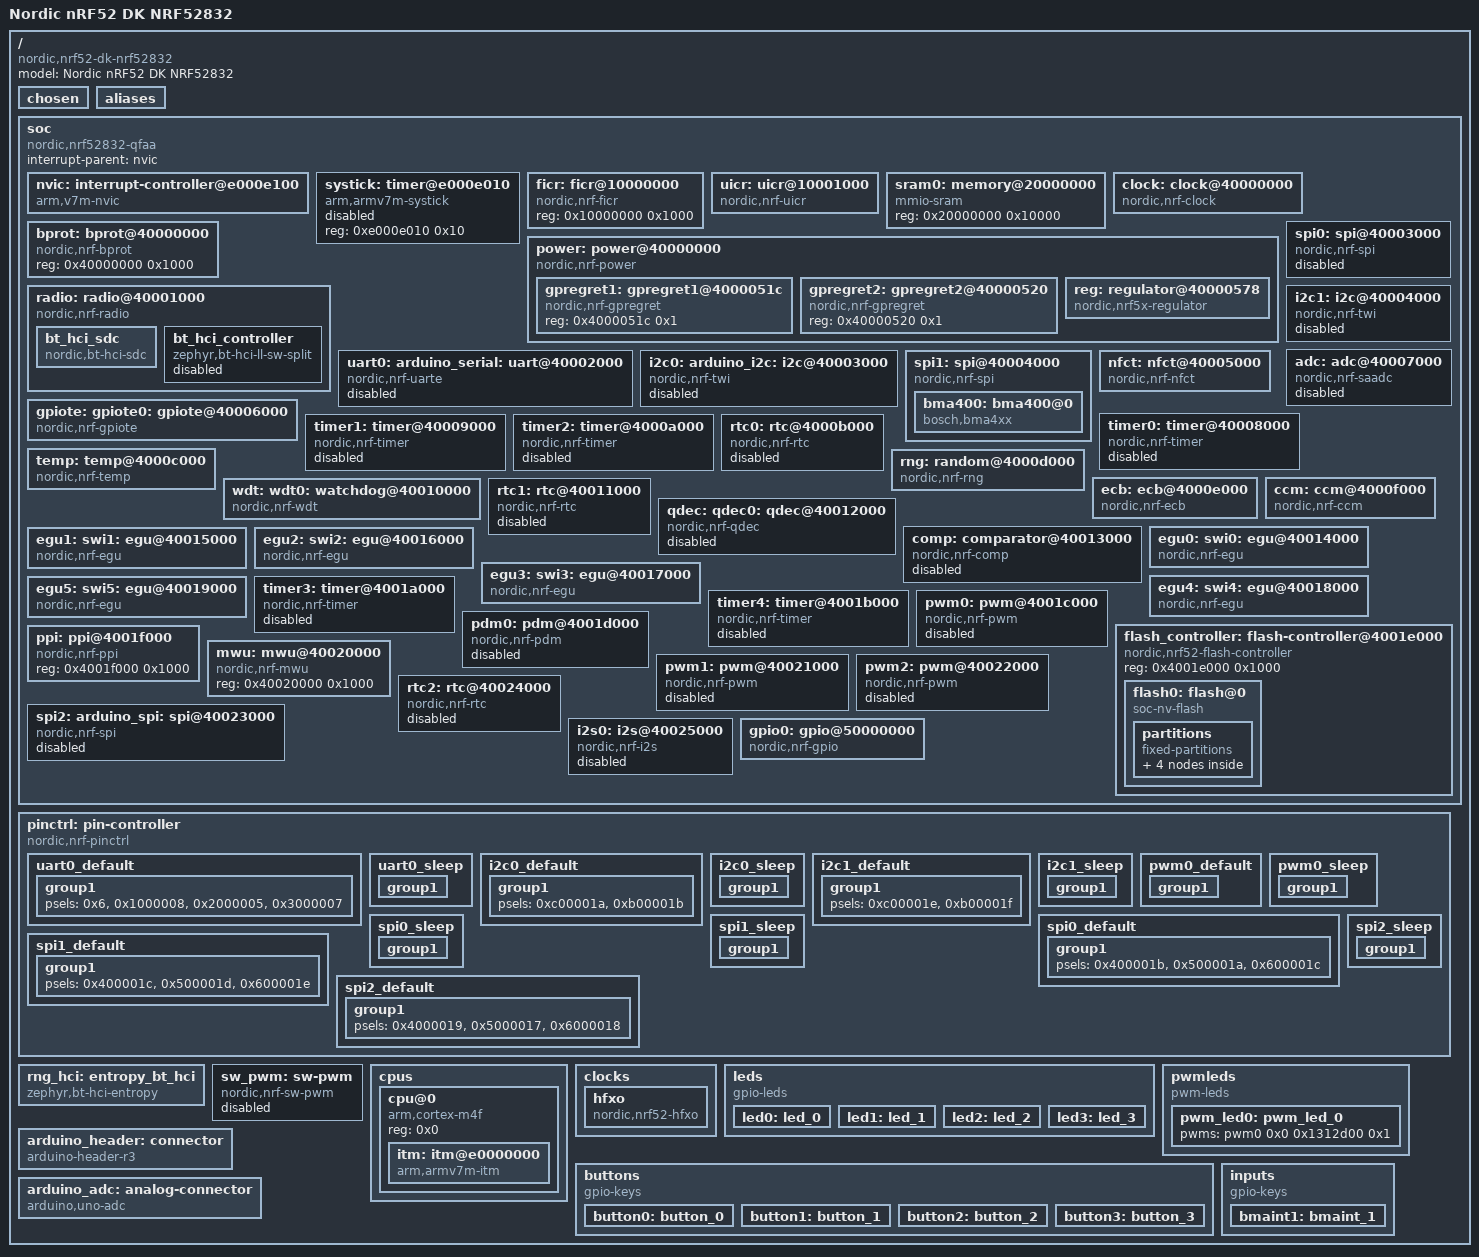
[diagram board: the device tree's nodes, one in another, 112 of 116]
/dts-v1/;

/* node '/' defined in zephyr/dts/common/skeleton.dtsi:9 */
/ {
	#address-cells = < 0x1 >;                /* in zephyr/dts/common/skeleton.dtsi:10 */
	#size-cells = < 0x1 >;                   /* in zephyr/dts/common/skeleton.dtsi:11 */
	model = "Nordic nRF52 DK NRF52832";      /* in zephyr/boards/nordic/nrf52dk/nrf52dk_nrf52832.dts:14 */
	compatible = "nordic,nrf52-dk-nrf52832"; /* in zephyr/boards/nordic/nrf52dk/nrf52dk_nrf52832.dts:15 */

	/* node '/chosen' defined in zephyr/dts/common/skeleton.dtsi:12 */
	chosen {
		zephyr,bt-hci = &bt_hci_sdc;                 /* in zephyr/dts/arm/nordic/nrf52832.dtsi:10 */
		zephyr,entropy = &rng;                       /* in zephyr/dts/arm/nordic/nrf52832.dtsi:11 */
		zephyr,flash-controller = &flash_controller; /* in zephyr/dts/arm/nordic/nrf52832.dtsi:12 */
		zephyr,console = &uart0;                     /* in zephyr/boards/nordic/nrf52dk/nrf52dk_nrf52832.dts:18 */
		zephyr,shell-uart = &uart0;                  /* in zephyr/boards/nordic/nrf52dk/nrf52dk_nrf52832.dts:19 */
		zephyr,uart-mcumgr = &uart0;                 /* in zephyr/boards/nordic/nrf52dk/nrf52dk_nrf52832.dts:20 */
		zephyr,bt-mon-uart = &uart0;                 /* in zephyr/boards/nordic/nrf52dk/nrf52dk_nrf52832.dts:21 */
		zephyr,bt-c2h-uart = &uart0;                 /* in zephyr/boards/nordic/nrf52dk/nrf52dk_nrf52832.dts:22 */
		zephyr,sram = &sram0;                        /* in zephyr/boards/nordic/nrf52dk/nrf52dk_nrf52832.dts:23 */
		zephyr,flash = &flash0;                      /* in zephyr/boards/nordic/nrf52dk/nrf52dk_nrf52832.dts:24 */
		zephyr,code-partition = &slot0_partition;    /* in zephyr/boards/nordic/nrf52dk/nrf52dk_nrf52832.dts:25 */
	};

	/* node '/aliases' defined in zephyr/dts/common/skeleton.dtsi:13 */
	aliases {
		led0 = &led0;               /* in zephyr/boards/nordic/nrf52dk/nrf52dk_nrf52832.dts:130 */
		led1 = &led1;               /* in zephyr/boards/nordic/nrf52dk/nrf52dk_nrf52832.dts:131 */
		led2 = &led2;               /* in zephyr/boards/nordic/nrf52dk/nrf52dk_nrf52832.dts:132 */
		led3 = &led3;               /* in zephyr/boards/nordic/nrf52dk/nrf52dk_nrf52832.dts:133 */
		pwm-led0 = &pwm_led0;       /* in zephyr/boards/nordic/nrf52dk/nrf52dk_nrf52832.dts:134 */
		sw0 = &button0;             /* in zephyr/boards/nordic/nrf52dk/nrf52dk_nrf52832.dts:135 */
		sw1 = &button1;             /* in zephyr/boards/nordic/nrf52dk/nrf52dk_nrf52832.dts:136 */
		sw2 = &button2;             /* in zephyr/boards/nordic/nrf52dk/nrf52dk_nrf52832.dts:137 */
		sw3 = &button3;             /* in zephyr/boards/nordic/nrf52dk/nrf52dk_nrf52832.dts:138 */
		bootloader-led0 = &led0;    /* in zephyr/boards/nordic/nrf52dk/nrf52dk_nrf52832.dts:139 */
		mcuboot-button0 = &button0; /* in zephyr/boards/nordic/nrf52dk/nrf52dk_nrf52832.dts:140 */
		mcuboot-led0 = &led0;       /* in zephyr/boards/nordic/nrf52dk/nrf52dk_nrf52832.dts:141 */
		watchdog0 = &wdt0;          /* in zephyr/boards/nordic/nrf52dk/nrf52dk_nrf52832.dts:142 */
		int1 = &bmaint1;            /* in ../../Desktop/SeniorDesign/bma400_sample/boards/nrf52dk_nrf52832.overlay:13 */
	};

	/* node '/soc' defined in zephyr/dts/arm/armv7-m.dtsi:6 */
	soc {
		#address-cells = < 0x1 >;            /* in zephyr/dts/arm/armv7-m.dtsi:7 */
		#size-cells = < 0x1 >;               /* in zephyr/dts/arm/armv7-m.dtsi:8 */
		compatible = "nordic,nrf52832-qfaa",
		             "nordic,nrf52832",
		             "nordic,nrf52",
		             "simple-bus";           /* in zephyr/dts/arm/nordic/nrf52832_qfaa.dtsi:20 */
		interrupt-parent = < &nvic >;        /* in zephyr/dts/arm/armv7-m.dtsi:10 */
		ranges;                              /* in zephyr/dts/arm/armv7-m.dtsi:11 */

		/* node '/soc/interrupt-controller@e000e100' defined in zephyr/dts/arm/armv7-m.dtsi:13 */
		nvic: interrupt-controller@e000e100 {
			#address-cells = < 0x1 >;            /* in zephyr/dts/arm/armv7-m.dtsi:14 */
			compatible = "arm,v7m-nvic";         /* in zephyr/dts/arm/armv7-m.dtsi:15 */
			reg = < 0xe000e100 0xc00 >;          /* in zephyr/dts/arm/armv7-m.dtsi:16 */
			interrupt-controller;                /* in zephyr/dts/arm/armv7-m.dtsi:17 */
			#interrupt-cells = < 0x2 >;          /* in zephyr/dts/arm/armv7-m.dtsi:18 */
			arm,num-irq-priority-bits = < 0x3 >; /* in zephyr/dts/arm/nordic/nrf52832.dtsi:502 */
			phandle = < 0x1 >;                   /* in zephyr/dts/arm/armv7-m.dtsi:10 */
		};

		/* node '/soc/timer@e000e010' defined in zephyr/dts/arm/armv7-m.dtsi:21 */
		systick: timer@e000e010 {
			compatible = "arm,armv7m-systick"; /* in zephyr/dts/arm/armv7-m.dtsi:22 */
			reg = < 0xe000e010 0x10 >;         /* in zephyr/dts/arm/armv7-m.dtsi:23 */
			status = "disabled";               /* in zephyr/dts/arm/nordic/nrf52832.dtsi:507 */
		};

		/* node '/soc/ficr@10000000' defined in zephyr/dts/arm/nordic/nrf52832.dtsi:44 */
		ficr: ficr@10000000 {
			compatible = "nordic,nrf-ficr"; /* in zephyr/dts/arm/nordic/nrf52832.dtsi:45 */
			reg = < 0x10000000 0x1000 >;    /* in zephyr/dts/arm/nordic/nrf52832.dtsi:46 */
			#nordic,ficr-cells = < 0x1 >;   /* in zephyr/dts/arm/nordic/nrf52832.dtsi:47 */
			status = "okay";                /* in zephyr/dts/arm/nordic/nrf52832.dtsi:48 */
		};

		/* node '/soc/uicr@10001000' defined in zephyr/dts/arm/nordic/nrf52832.dtsi:51 */
		uicr: uicr@10001000 {
			compatible = "nordic,nrf-uicr"; /* in zephyr/dts/arm/nordic/nrf52832.dtsi:52 */
			reg = < 0x10001000 0x1000 >;    /* in zephyr/dts/arm/nordic/nrf52832.dtsi:53 */
			status = "okay";                /* in zephyr/dts/arm/nordic/nrf52832.dtsi:54 */
			gpio-as-nreset;                 /* in zephyr/boards/nordic/nrf52dk/nrf52dk_nrf52832.dts:155 */
		};

		/* node '/soc/memory@20000000' defined in zephyr/dts/arm/nordic/nrf52832.dtsi:57 */
		sram0: memory@20000000 {
			compatible = "mmio-sram";     /* in zephyr/dts/arm/nordic/nrf52832.dtsi:58 */
			reg = < 0x20000000 0x10000 >; /* in zephyr/dts/arm/nordic/nrf52832_qfaa.dtsi:15 */
		};

		/* node '/soc/clock@40000000' defined in zephyr/dts/arm/nordic/nrf52832.dtsi:61 */
		clock: clock@40000000 {
			compatible = "nordic,nrf-clock"; /* in zephyr/dts/arm/nordic/nrf52832.dtsi:62 */
			reg = < 0x40000000 0x1000 >;     /* in zephyr/dts/arm/nordic/nrf52832.dtsi:63 */
			interrupts = < 0x0 0x1 >;        /* in zephyr/dts/arm/nordic/nrf52832.dtsi:64 */
			status = "okay";                 /* in zephyr/dts/arm/nordic/nrf52832.dtsi:65 */
		};

		/* node '/soc/power@40000000' defined in zephyr/dts/arm/nordic/nrf52832.dtsi:68 */
		power: power@40000000 {
			compatible = "nordic,nrf-power"; /* in zephyr/dts/arm/nordic/nrf52832.dtsi:69 */
			reg = < 0x40000000 0x1000 >;     /* in zephyr/dts/arm/nordic/nrf52832.dtsi:70 */
			interrupts = < 0x0 0x1 >;        /* in zephyr/dts/arm/nordic/nrf52832.dtsi:71 */
			status = "okay";                 /* in zephyr/dts/arm/nordic/nrf52832.dtsi:72 */
			#address-cells = < 0x1 >;        /* in zephyr/dts/arm/nordic/nrf52832.dtsi:73 */
			#size-cells = < 0x1 >;           /* in zephyr/dts/arm/nordic/nrf52832.dtsi:74 */

			/* node '/soc/power@40000000/gpregret1@4000051c' defined in zephyr/dts/arm/nordic/nrf52832.dtsi:76 */
			gpregret1: gpregret1@4000051c {
				#address-cells = < 0x1 >;           /* in zephyr/dts/arm/nordic/nrf52832.dtsi:77 */
				#size-cells = < 0x1 >;              /* in zephyr/dts/arm/nordic/nrf52832.dtsi:78 */
				compatible = "nordic,nrf-gpregret"; /* in zephyr/dts/arm/nordic/nrf52832.dtsi:79 */
				reg = < 0x4000051c 0x1 >;           /* in zephyr/dts/arm/nordic/nrf52832.dtsi:80 */
				status = "okay";                    /* in zephyr/dts/arm/nordic/nrf52832.dtsi:81 */
			};

			/* node '/soc/power@40000000/gpregret2@40000520' defined in zephyr/dts/arm/nordic/nrf52832.dtsi:84 */
			gpregret2: gpregret2@40000520 {
				#address-cells = < 0x1 >;           /* in zephyr/dts/arm/nordic/nrf52832.dtsi:85 */
				#size-cells = < 0x1 >;              /* in zephyr/dts/arm/nordic/nrf52832.dtsi:86 */
				compatible = "nordic,nrf-gpregret"; /* in zephyr/dts/arm/nordic/nrf52832.dtsi:87 */
				reg = < 0x40000520 0x1 >;           /* in zephyr/dts/arm/nordic/nrf52832.dtsi:88 */
				status = "okay";                    /* in zephyr/dts/arm/nordic/nrf52832.dtsi:89 */
			};

			/* node '/soc/power@40000000/regulator@40000578' defined in zephyr/dts/arm/nordic/nrf52832.dtsi:92 */
			reg: regulator@40000578 {
				compatible = "nordic,nrf5x-regulator"; /* in zephyr/dts/arm/nordic/nrf52832.dtsi:93 */
				reg = < 0x40000578 0x1 >;              /* in zephyr/dts/arm/nordic/nrf52832.dtsi:94 */
				regulator-name = "REG";                /* in zephyr/dts/arm/nordic/nrf52832.dtsi:95 */
				regulator-initial-mode = < 0x1 >;      /* in zephyr/boards/nordic/nrf52dk/nrf52dk_nrf52832.dts:147 */
			};
		};

		/* node '/soc/bprot@40000000' defined in zephyr/dts/arm/nordic/nrf52832.dtsi:100 */
		bprot: bprot@40000000 {
			compatible = "nordic,nrf-bprot"; /* in zephyr/dts/arm/nordic/nrf52832.dtsi:101 */
			reg = < 0x40000000 0x1000 >;     /* in zephyr/dts/arm/nordic/nrf52832.dtsi:102 */
			status = "okay";                 /* in zephyr/dts/arm/nordic/nrf52832.dtsi:103 */
		};

		/* node '/soc/radio@40001000' defined in zephyr/dts/arm/nordic/nrf52832.dtsi:106 */
		radio: radio@40001000 {
			compatible = "nordic,nrf-radio"; /* in zephyr/dts/arm/nordic/nrf52832.dtsi:107 */
			reg = < 0x40001000 0x1000 >;     /* in zephyr/dts/arm/nordic/nrf52832.dtsi:108 */
			interrupts = < 0x1 0x1 >;        /* in zephyr/dts/arm/nordic/nrf52832.dtsi:109 */
			status = "okay";                 /* in zephyr/dts/arm/nordic/nrf52832.dtsi:110 */
			ble-2mbps-supported;             /* in zephyr/dts/arm/nordic/nrf52832.dtsi:111 */

			/* node '/soc/radio@40001000/bt_hci_sdc' defined in zephyr/dts/arm/nordic/nrf52832.dtsi:113 */
			bt_hci_sdc: bt_hci_sdc {
				compatible = "nordic,bt-hci-sdc"; /* in zephyr/dts/arm/nordic/nrf52832.dtsi:114 */
				status = "okay";                  /* in zephyr/dts/arm/nordic/nrf52832.dtsi:115 */
			};

			/* node '/soc/radio@40001000/bt_hci_controller' defined in zephyr/dts/arm/nordic/nrf52832.dtsi:117 */
			bt_hci_controller: bt_hci_controller {
				compatible = "zephyr,bt-hci-ll-sw-split"; /* in zephyr/dts/arm/nordic/nrf52832.dtsi:118 */
				status = "disabled";                      /* in zephyr/dts/arm/nordic/nrf52832.dtsi:119 */
			};
		};

		/* node '/soc/uart@40002000' defined in zephyr/dts/arm/nordic/nrf52832.dtsi:123 */
		uart0: arduino_serial: uart@40002000 {
			compatible = "nordic,nrf-uarte"; /* in zephyr/boards/nordic/nrf52dk/nrf52dk_nrf52832.dts:172 */
			reg = < 0x40002000 0x1000 >;     /* in zephyr/dts/arm/nordic/nrf52832.dtsi:127 */
			interrupts = < 0x2 0x1 >;        /* in zephyr/dts/arm/nordic/nrf52832.dtsi:128 */
			status = "disabled";             /* in ../../Desktop/SeniorDesign/bma400_sample/boards/nrf52dk_nrf52832.overlay:21 */
			current-speed = < 0x1c200 >;     /* in zephyr/boards/nordic/nrf52dk/nrf52dk_nrf52832.dts:173 */
			pinctrl-0 = < &uart0_default >;  /* in zephyr/boards/nordic/nrf52dk/nrf52dk_nrf52832.dts:174 */
			pinctrl-1 = < &uart0_sleep >;    /* in zephyr/boards/nordic/nrf52dk/nrf52dk_nrf52832.dts:175 */
			pinctrl-names = "default",
			                "sleep";         /* in zephyr/boards/nordic/nrf52dk/nrf52dk_nrf52832.dts:176 */
		};

		/* node '/soc/i2c@40003000' defined in zephyr/dts/arm/nordic/nrf52832.dtsi:132 */
		i2c0: arduino_i2c: i2c@40003000 {
			compatible = "nordic,nrf-twi"; /* in zephyr/boards/nordic/nrf52dk/nrf52dk_nrf52832.dts:180 */
			#address-cells = < 0x1 >;      /* in zephyr/dts/arm/nordic/nrf52832.dtsi:141 */
			#size-cells = < 0x0 >;         /* in zephyr/dts/arm/nordic/nrf52832.dtsi:142 */
			reg = < 0x40003000 0x1000 >;   /* in zephyr/dts/arm/nordic/nrf52832.dtsi:143 */
			interrupts = < 0x3 0x1 >;      /* in zephyr/dts/arm/nordic/nrf52832.dtsi:144 */
			easydma-maxcnt-bits = < 0x8 >; /* in zephyr/dts/arm/nordic/nrf52832.dtsi:145 */
			status = "disabled";           /* in ../../Desktop/SeniorDesign/bma400_sample/boards/nrf52dk_nrf52832.overlay:18 */
			zephyr,pm-device-runtime-auto; /* in zephyr/dts/arm/nordic/nrf52832.dtsi:147 */
			pinctrl-0 = < &i2c0_default >; /* in zephyr/boards/nordic/nrf52dk/nrf52dk_nrf52832.dts:182 */
			pinctrl-1 = < &i2c0_sleep >;   /* in zephyr/boards/nordic/nrf52dk/nrf52dk_nrf52832.dts:183 */
			pinctrl-names = "default",
			                "sleep";       /* in zephyr/boards/nordic/nrf52dk/nrf52dk_nrf52832.dts:184 */
		};

		/* node '/soc/spi@40003000' defined in zephyr/dts/arm/nordic/nrf52832.dtsi:150 */
		spi0: spi@40003000 {
			compatible = "nordic,nrf-spi"; /* in zephyr/boards/nordic/nrf52dk/nrf52dk_nrf52832.dts:204 */
			#address-cells = < 0x1 >;      /* in zephyr/dts/arm/nordic/nrf52832.dtsi:159 */
			#size-cells = < 0x0 >;         /* in zephyr/dts/arm/nordic/nrf52832.dtsi:160 */
			reg = < 0x40003000 0x1000 >;   /* in zephyr/dts/arm/nordic/nrf52832.dtsi:161 */
			interrupts = < 0x3 0x1 >;      /* in zephyr/dts/arm/nordic/nrf52832.dtsi:162 */
			max-frequency = < 0x7a1200 >;  /* in zephyr/dts/arm/nordic/nrf52832.dtsi:163 */
			easydma-maxcnt-bits = < 0x8 >; /* in zephyr/dts/arm/nordic/nrf52832.dtsi:164 */
			status = "disabled";           /* in ../../Desktop/SeniorDesign/bma400_sample/boards/nrf52dk_nrf52832.overlay:19 */
			pinctrl-0 = < &spi0_default >; /* in zephyr/boards/nordic/nrf52dk/nrf52dk_nrf52832.dts:207 */
			pinctrl-1 = < &spi0_sleep >;   /* in zephyr/boards/nordic/nrf52dk/nrf52dk_nrf52832.dts:208 */
			pinctrl-names = "default",
			                "sleep";       /* in zephyr/boards/nordic/nrf52dk/nrf52dk_nrf52832.dts:209 */
		};

		/* node '/soc/i2c@40004000' defined in zephyr/dts/arm/nordic/nrf52832.dtsi:168 */
		i2c1: i2c@40004000 {
			compatible = "nordic,nrf-twi"; /* in zephyr/boards/nordic/nrf52dk/nrf52dk_nrf52832.dts:188 */
			#address-cells = < 0x1 >;      /* in zephyr/dts/arm/nordic/nrf52832.dtsi:177 */
			#size-cells = < 0x0 >;         /* in zephyr/dts/arm/nordic/nrf52832.dtsi:178 */
			reg = < 0x40004000 0x1000 >;   /* in zephyr/dts/arm/nordic/nrf52832.dtsi:179 */
			interrupts = < 0x4 0x1 >;      /* in zephyr/dts/arm/nordic/nrf52832.dtsi:180 */
			easydma-maxcnt-bits = < 0x8 >; /* in zephyr/dts/arm/nordic/nrf52832.dtsi:181 */
			status = "disabled";           /* in ../../Desktop/SeniorDesign/bma400_sample/boards/nrf52dk_nrf52832.overlay:20 */
			zephyr,pm-device-runtime-auto; /* in zephyr/dts/arm/nordic/nrf52832.dtsi:183 */
			pinctrl-0 = < &i2c1_default >; /* in zephyr/boards/nordic/nrf52dk/nrf52dk_nrf52832.dts:191 */
			pinctrl-1 = < &i2c1_sleep >;   /* in zephyr/boards/nordic/nrf52dk/nrf52dk_nrf52832.dts:192 */
			pinctrl-names = "default",
			                "sleep";       /* in zephyr/boards/nordic/nrf52dk/nrf52dk_nrf52832.dts:193 */
		};

		/* node '/soc/spi@40004000' defined in zephyr/dts/arm/nordic/nrf52832.dtsi:186 */
		spi1: spi@40004000 {
			compatible = "nordic,nrf-spi";  /* in ../../Desktop/SeniorDesign/bma400_sample/boards/nrf52dk_nrf52832.overlay:31 */
			#address-cells = < 0x1 >;       /* in zephyr/dts/arm/nordic/nrf52832.dtsi:195 */
			#size-cells = < 0x0 >;          /* in zephyr/dts/arm/nordic/nrf52832.dtsi:196 */
			reg = < 0x40004000 0x1000 >;    /* in zephyr/dts/arm/nordic/nrf52832.dtsi:197 */
			interrupts = < 0x4 0x1 >;       /* in zephyr/dts/arm/nordic/nrf52832.dtsi:198 */
			max-frequency = < 0x7a1200 >;   /* in zephyr/dts/arm/nordic/nrf52832.dtsi:199 */
			easydma-maxcnt-bits = < 0x8 >;  /* in zephyr/dts/arm/nordic/nrf52832.dtsi:200 */
			status = "okay";                /* in ../../Desktop/SeniorDesign/bma400_sample/boards/nrf52dk_nrf52832.overlay:32 */
			pinctrl-0 = < &spi1_default >;  /* in ../../Desktop/SeniorDesign/bma400_sample/boards/nrf52dk_nrf52832.overlay:33 */
			pinctrl-1 = < &spi1_sleep >;    /* in ../../Desktop/SeniorDesign/bma400_sample/boards/nrf52dk_nrf52832.overlay:34 */
			pinctrl-names = "default",
			                "sleep";        /* in ../../Desktop/SeniorDesign/bma400_sample/boards/nrf52dk_nrf52832.overlay:35 */
			cs-gpios = < &gpio0 0x1a 0x1 >; /* in ../../Desktop/SeniorDesign/bma400_sample/boards/nrf52dk_nrf52832.overlay:36 */

			/* node '/soc/spi@40004000/bma400@0' defined in ../../Desktop/SeniorDesign/bma400_sample/boards/nrf52dk_nrf52832.overlay:37 */
			bma400: bma400@0 {
				compatible = "bosch,bma4xx";     /* in ../../Desktop/SeniorDesign/bma400_sample/boards/nrf52dk_nrf52832.overlay:38 */
				reg = < 0x0 >;                   /* in ../../Desktop/SeniorDesign/bma400_sample/boards/nrf52dk_nrf52832.overlay:39 */
				spi-max-frequency = < 0xf4240 >; /* in ../../Desktop/SeniorDesign/bma400_sample/boards/nrf52dk_nrf52832.overlay:40 */
			};
		};

		/* node '/soc/nfct@40005000' defined in zephyr/dts/arm/nordic/nrf52832.dtsi:204 */
		nfct: nfct@40005000 {
			compatible = "nordic,nrf-nfct"; /* in zephyr/dts/arm/nordic/nrf52832.dtsi:205 */
			reg = < 0x40005000 0x1000 >;    /* in zephyr/dts/arm/nordic/nrf52832.dtsi:206 */
			interrupts = < 0x5 0x1 >;       /* in zephyr/dts/arm/nordic/nrf52832.dtsi:207 */
			status = "okay";                /* in zephyr/boards/nordic/nrf52dk/nrf52dk_nrf52832.dts:159 */
		};

		/* node '/soc/gpiote@40006000' defined in zephyr/dts/arm/nordic/nrf52832.dtsi:211 */
		gpiote: gpiote0: gpiote@40006000 {
			compatible = "nordic,nrf-gpiote"; /* in zephyr/dts/arm/nordic/nrf52832.dtsi:212 */
			reg = < 0x40006000 0x1000 >;      /* in zephyr/dts/arm/nordic/nrf52832.dtsi:213 */
			interrupts = < 0x6 0x5 >;         /* in zephyr/dts/arm/nordic/nrf52832.dtsi:214 */
			status = "okay";                  /* in zephyr/boards/nordic/nrf52dk/nrf52dk_nrf52832.dts:163 */
			instance = < 0x0 >;               /* in zephyr/dts/arm/nordic/nrf52832.dtsi:216 */
			phandle = < 0x12 >;               /* in zephyr/dts/arm/nordic/nrf52832.dtsi:496 */
		};

		/* node '/soc/adc@40007000' defined in zephyr/dts/arm/nordic/nrf52832.dtsi:219 */
		adc: adc@40007000 {
			compatible = "nordic,nrf-saadc"; /* in zephyr/dts/arm/nordic/nrf52832.dtsi:220 */
			reg = < 0x40007000 0x1000 >;     /* in zephyr/dts/arm/nordic/nrf52832.dtsi:221 */
			interrupts = < 0x7 0x1 >;        /* in zephyr/dts/arm/nordic/nrf52832.dtsi:222 */
			status = "disabled";             /* in ../../Desktop/SeniorDesign/bma400_sample/boards/nrf52dk_nrf52832.overlay:24 */
			#io-channel-cells = < 0x1 >;     /* in zephyr/dts/arm/nordic/nrf52832.dtsi:224 */
			zephyr,pm-device-runtime-auto;   /* in zephyr/dts/arm/nordic/nrf52832.dtsi:225 */
			phandle = < 0x15 >;              /* in zephyr/boards/nordic/nrf52dk/nrf52dk_nrf52832.dts:120 */
		};

		/* node '/soc/timer@40008000' defined in zephyr/dts/arm/nordic/nrf52832.dtsi:228 */
		timer0: timer@40008000 {
			compatible = "nordic,nrf-timer"; /* in zephyr/dts/arm/nordic/nrf52832.dtsi:229 */
			status = "disabled";             /* in zephyr/dts/arm/nordic/nrf52832.dtsi:230 */
			reg = < 0x40008000 0x1000 >;     /* in zephyr/dts/arm/nordic/nrf52832.dtsi:231 */
			cc-num = < 0x4 >;                /* in zephyr/dts/arm/nordic/nrf52832.dtsi:232 */
			max-bit-width = < 0x20 >;        /* in zephyr/dts/arm/nordic/nrf52832.dtsi:233 */
			interrupts = < 0x8 0x1 >;        /* in zephyr/dts/arm/nordic/nrf52832.dtsi:234 */
			prescaler = < 0x0 >;             /* in zephyr/dts/arm/nordic/nrf52832.dtsi:235 */
		};

		/* node '/soc/timer@40009000' defined in zephyr/dts/arm/nordic/nrf52832.dtsi:238 */
		timer1: timer@40009000 {
			compatible = "nordic,nrf-timer"; /* in zephyr/dts/arm/nordic/nrf52832.dtsi:239 */
			status = "disabled";             /* in zephyr/dts/arm/nordic/nrf52832.dtsi:240 */
			reg = < 0x40009000 0x1000 >;     /* in zephyr/dts/arm/nordic/nrf52832.dtsi:241 */
			cc-num = < 0x4 >;                /* in zephyr/dts/arm/nordic/nrf52832.dtsi:242 */
			max-bit-width = < 0x20 >;        /* in zephyr/dts/arm/nordic/nrf52832.dtsi:243 */
			interrupts = < 0x9 0x1 >;        /* in zephyr/dts/arm/nordic/nrf52832.dtsi:244 */
			prescaler = < 0x0 >;             /* in zephyr/dts/arm/nordic/nrf52832.dtsi:245 */
			phandle = < 0x13 >;              /* in zephyr/dts/vendor/nordic/nrf_common.dtsi:41 */
		};

		/* node '/soc/timer@4000a000' defined in zephyr/dts/arm/nordic/nrf52832.dtsi:248 */
		timer2: timer@4000a000 {
			compatible = "nordic,nrf-timer"; /* in zephyr/dts/arm/nordic/nrf52832.dtsi:249 */
			status = "disabled";             /* in zephyr/dts/arm/nordic/nrf52832.dtsi:250 */
			reg = < 0x4000a000 0x1000 >;     /* in zephyr/dts/arm/nordic/nrf52832.dtsi:251 */
			cc-num = < 0x4 >;                /* in zephyr/dts/arm/nordic/nrf52832.dtsi:252 */
			max-bit-width = < 0x20 >;        /* in zephyr/dts/arm/nordic/nrf52832.dtsi:253 */
			interrupts = < 0xa 0x1 >;        /* in zephyr/dts/arm/nordic/nrf52832.dtsi:254 */
			prescaler = < 0x0 >;             /* in zephyr/dts/arm/nordic/nrf52832.dtsi:255 */
		};

		/* node '/soc/rtc@4000b000' defined in zephyr/dts/arm/nordic/nrf52832.dtsi:258 */
		rtc0: rtc@4000b000 {
			compatible = "nordic,nrf-rtc"; /* in zephyr/dts/arm/nordic/nrf52832.dtsi:259 */
			reg = < 0x4000b000 0x1000 >;   /* in zephyr/dts/arm/nordic/nrf52832.dtsi:260 */
			cc-num = < 0x3 >;              /* in zephyr/dts/arm/nordic/nrf52832.dtsi:261 */
			interrupts = < 0xb 0x1 >;      /* in zephyr/dts/arm/nordic/nrf52832.dtsi:262 */
			status = "disabled";           /* in zephyr/dts/arm/nordic/nrf52832.dtsi:263 */
			clock-frequency = < 0x8000 >;  /* in zephyr/dts/arm/nordic/nrf52832.dtsi:264 */
			prescaler = < 0x1 >;           /* in zephyr/dts/arm/nordic/nrf52832.dtsi:265 */
		};

		/* node '/soc/temp@4000c000' defined in zephyr/dts/arm/nordic/nrf52832.dtsi:268 */
		temp: temp@4000c000 {
			compatible = "nordic,nrf-temp"; /* in zephyr/dts/arm/nordic/nrf52832.dtsi:269 */
			reg = < 0x4000c000 0x1000 >;    /* in zephyr/dts/arm/nordic/nrf52832.dtsi:270 */
			interrupts = < 0xc 0x1 >;       /* in zephyr/dts/arm/nordic/nrf52832.dtsi:271 */
			status = "okay";                /* in zephyr/dts/arm/nordic/nrf52832.dtsi:272 */
		};

		/* node '/soc/random@4000d000' defined in zephyr/dts/arm/nordic/nrf52832.dtsi:275 */
		rng: random@4000d000 {
			compatible = "nordic,nrf-rng"; /* in zephyr/dts/arm/nordic/nrf52832.dtsi:276 */
			reg = < 0x4000d000 0x1000 >;   /* in zephyr/dts/arm/nordic/nrf52832.dtsi:277 */
			interrupts = < 0xd 0x1 >;      /* in zephyr/dts/arm/nordic/nrf52832.dtsi:278 */
			status = "okay";               /* in zephyr/dts/arm/nordic/nrf52832.dtsi:279 */
		};

		/* node '/soc/ecb@4000e000' defined in zephyr/dts/arm/nordic/nrf52832.dtsi:282 */
		ecb: ecb@4000e000 {
			compatible = "nordic,nrf-ecb"; /* in zephyr/dts/arm/nordic/nrf52832.dtsi:283 */
			reg = < 0x4000e000 0x1000 >;   /* in zephyr/dts/arm/nordic/nrf52832.dtsi:284 */
			interrupts = < 0xe 0x1 >;      /* in zephyr/dts/arm/nordic/nrf52832.dtsi:285 */
			status = "okay";               /* in zephyr/dts/arm/nordic/nrf52832.dtsi:286 */
		};

		/* node '/soc/ccm@4000f000' defined in zephyr/dts/arm/nordic/nrf52832.dtsi:289 */
		ccm: ccm@4000f000 {
			compatible = "nordic,nrf-ccm"; /* in zephyr/dts/arm/nordic/nrf52832.dtsi:290 */
			reg = < 0x4000f000 0x1000 >;   /* in zephyr/dts/arm/nordic/nrf52832.dtsi:291 */
			interrupts = < 0xf 0x1 >;      /* in zephyr/dts/arm/nordic/nrf52832.dtsi:292 */
			length-field-length-8-bits;    /* in zephyr/dts/arm/nordic/nrf52832.dtsi:293 */
			status = "okay";               /* in zephyr/dts/arm/nordic/nrf52832.dtsi:294 */
		};

		/* node '/soc/watchdog@40010000' defined in zephyr/dts/arm/nordic/nrf52832.dtsi:297 */
		wdt: wdt0: watchdog@40010000 {
			compatible = "nordic,nrf-wdt"; /* in zephyr/dts/arm/nordic/nrf52832.dtsi:298 */
			reg = < 0x40010000 0x1000 >;   /* in zephyr/dts/arm/nordic/nrf52832.dtsi:299 */
			interrupts = < 0x10 0x1 >;     /* in zephyr/dts/arm/nordic/nrf52832.dtsi:300 */
			status = "okay";               /* in zephyr/dts/arm/nordic/nrf52832.dtsi:301 */
		};

		/* node '/soc/rtc@40011000' defined in zephyr/dts/arm/nordic/nrf52832.dtsi:304 */
		rtc1: rtc@40011000 {
			compatible = "nordic,nrf-rtc"; /* in zephyr/dts/arm/nordic/nrf52832.dtsi:305 */
			reg = < 0x40011000 0x1000 >;   /* in zephyr/dts/arm/nordic/nrf52832.dtsi:306 */
			cc-num = < 0x4 >;              /* in zephyr/dts/arm/nordic/nrf52832.dtsi:307 */
			interrupts = < 0x11 0x1 >;     /* in zephyr/dts/arm/nordic/nrf52832.dtsi:308 */
			status = "disabled";           /* in zephyr/dts/arm/nordic/nrf52832.dtsi:309 */
			clock-frequency = < 0x8000 >;  /* in zephyr/dts/arm/nordic/nrf52832.dtsi:310 */
			prescaler = < 0x1 >;           /* in zephyr/dts/arm/nordic/nrf52832.dtsi:311 */
		};

		/* node '/soc/qdec@40012000' defined in zephyr/dts/arm/nordic/nrf52832.dtsi:314 */
		qdec: qdec0: qdec@40012000 {
			compatible = "nordic,nrf-qdec"; /* in zephyr/dts/arm/nordic/nrf52832.dtsi:315 */
			reg = < 0x40012000 0x1000 >;    /* in zephyr/dts/arm/nordic/nrf52832.dtsi:316 */
			interrupts = < 0x12 0x1 >;      /* in zephyr/dts/arm/nordic/nrf52832.dtsi:317 */
			status = "disabled";            /* in zephyr/dts/arm/nordic/nrf52832.dtsi:318 */
		};

		/* node '/soc/comparator@40013000' defined in zephyr/dts/arm/nordic/nrf52832.dtsi:321 */
		comp: comparator@40013000 {
			compatible = "nordic,nrf-comp"; /* in zephyr/dts/arm/nordic/nrf52832.dtsi:326 */
			reg = < 0x40013000 0x1000 >;    /* in zephyr/dts/arm/nordic/nrf52832.dtsi:327 */
			interrupts = < 0x13 0x1 >;      /* in zephyr/dts/arm/nordic/nrf52832.dtsi:328 */
			status = "disabled";            /* in zephyr/dts/arm/nordic/nrf52832.dtsi:329 */
		};

		/* node '/soc/egu@40014000' defined in zephyr/dts/arm/nordic/nrf52832.dtsi:332 */
		egu0: swi0: egu@40014000 {
			compatible = "nordic,nrf-egu",
			             "nordic,nrf-swi"; /* in zephyr/dts/arm/nordic/nrf52832.dtsi:333 */
			reg = < 0x40014000 0x1000 >;   /* in zephyr/dts/arm/nordic/nrf52832.dtsi:334 */
			interrupts = < 0x14 0x1 >;     /* in zephyr/dts/arm/nordic/nrf52832.dtsi:335 */
			status = "okay";               /* in zephyr/dts/arm/nordic/nrf52832.dtsi:336 */
		};

		/* node '/soc/egu@40015000' defined in zephyr/dts/arm/nordic/nrf52832.dtsi:339 */
		egu1: swi1: egu@40015000 {
			compatible = "nordic,nrf-egu",
			             "nordic,nrf-swi"; /* in zephyr/dts/arm/nordic/nrf52832.dtsi:340 */
			reg = < 0x40015000 0x1000 >;   /* in zephyr/dts/arm/nordic/nrf52832.dtsi:341 */
			interrupts = < 0x15 0x1 >;     /* in zephyr/dts/arm/nordic/nrf52832.dtsi:342 */
			status = "okay";               /* in zephyr/dts/arm/nordic/nrf52832.dtsi:343 */
		};

		/* node '/soc/egu@40016000' defined in zephyr/dts/arm/nordic/nrf52832.dtsi:346 */
		egu2: swi2: egu@40016000 {
			compatible = "nordic,nrf-egu",
			             "nordic,nrf-swi"; /* in zephyr/dts/arm/nordic/nrf52832.dtsi:347 */
			reg = < 0x40016000 0x1000 >;   /* in zephyr/dts/arm/nordic/nrf52832.dtsi:348 */
			interrupts = < 0x16 0x1 >;     /* in zephyr/dts/arm/nordic/nrf52832.dtsi:349 */
			status = "okay";               /* in zephyr/dts/arm/nordic/nrf52832.dtsi:350 */
		};

		/* node '/soc/egu@40017000' defined in zephyr/dts/arm/nordic/nrf52832.dtsi:353 */
		egu3: swi3: egu@40017000 {
			compatible = "nordic,nrf-egu",
			             "nordic,nrf-swi"; /* in zephyr/dts/arm/nordic/nrf52832.dtsi:354 */
			reg = < 0x40017000 0x1000 >;   /* in zephyr/dts/arm/nordic/nrf52832.dtsi:355 */
			interrupts = < 0x17 0x1 >;     /* in zephyr/dts/arm/nordic/nrf52832.dtsi:356 */
			status = "okay";               /* in zephyr/dts/arm/nordic/nrf52832.dtsi:357 */
		};

		/* node '/soc/egu@40018000' defined in zephyr/dts/arm/nordic/nrf52832.dtsi:360 */
		egu4: swi4: egu@40018000 {
			compatible = "nordic,nrf-egu",
			             "nordic,nrf-swi"; /* in zephyr/dts/arm/nordic/nrf52832.dtsi:361 */
			reg = < 0x40018000 0x1000 >;   /* in zephyr/dts/arm/nordic/nrf52832.dtsi:362 */
			interrupts = < 0x18 0x1 >;     /* in zephyr/dts/arm/nordic/nrf52832.dtsi:363 */
			status = "okay";               /* in zephyr/dts/arm/nordic/nrf52832.dtsi:364 */
		};

		/* node '/soc/egu@40019000' defined in zephyr/dts/arm/nordic/nrf52832.dtsi:367 */
		egu5: swi5: egu@40019000 {
			compatible = "nordic,nrf-egu",
			             "nordic,nrf-swi"; /* in zephyr/dts/arm/nordic/nrf52832.dtsi:368 */
			reg = < 0x40019000 0x1000 >;   /* in zephyr/dts/arm/nordic/nrf52832.dtsi:369 */
			interrupts = < 0x19 0x1 >;     /* in zephyr/dts/arm/nordic/nrf52832.dtsi:370 */
			status = "okay";               /* in zephyr/dts/arm/nordic/nrf52832.dtsi:371 */
		};

		/* node '/soc/timer@4001a000' defined in zephyr/dts/arm/nordic/nrf52832.dtsi:374 */
		timer3: timer@4001a000 {
			compatible = "nordic,nrf-timer"; /* in zephyr/dts/arm/nordic/nrf52832.dtsi:375 */
			status = "disabled";             /* in zephyr/dts/arm/nordic/nrf52832.dtsi:376 */
			reg = < 0x4001a000 0x1000 >;     /* in zephyr/dts/arm/nordic/nrf52832.dtsi:377 */
			cc-num = < 0x6 >;                /* in zephyr/dts/arm/nordic/nrf52832.dtsi:378 */
			max-bit-width = < 0x20 >;        /* in zephyr/dts/arm/nordic/nrf52832.dtsi:379 */
			interrupts = < 0x1a 0x1 >;       /* in zephyr/dts/arm/nordic/nrf52832.dtsi:380 */
			prescaler = < 0x0 >;             /* in zephyr/dts/arm/nordic/nrf52832.dtsi:381 */
		};

		/* node '/soc/timer@4001b000' defined in zephyr/dts/arm/nordic/nrf52832.dtsi:384 */
		timer4: timer@4001b000 {
			compatible = "nordic,nrf-timer"; /* in zephyr/dts/arm/nordic/nrf52832.dtsi:385 */
			status = "disabled";             /* in zephyr/dts/arm/nordic/nrf52832.dtsi:386 */
			reg = < 0x4001b000 0x1000 >;     /* in zephyr/dts/arm/nordic/nrf52832.dtsi:387 */
			cc-num = < 0x6 >;                /* in zephyr/dts/arm/nordic/nrf52832.dtsi:388 */
			max-bit-width = < 0x20 >;        /* in zephyr/dts/arm/nordic/nrf52832.dtsi:389 */
			interrupts = < 0x1b 0x1 >;       /* in zephyr/dts/arm/nordic/nrf52832.dtsi:390 */
			prescaler = < 0x0 >;             /* in zephyr/dts/arm/nordic/nrf52832.dtsi:391 */
		};

		/* node '/soc/pwm@4001c000' defined in zephyr/dts/arm/nordic/nrf52832.dtsi:394 */
		pwm0: pwm@4001c000 {
			compatible = "nordic,nrf-pwm"; /* in zephyr/dts/arm/nordic/nrf52832.dtsi:395 */
			reg = < 0x4001c000 0x1000 >;   /* in zephyr/dts/arm/nordic/nrf52832.dtsi:396 */
			interrupts = < 0x1c 0x1 >;     /* in zephyr/dts/arm/nordic/nrf52832.dtsi:397 */
			status = "disabled";           /* in ../../Desktop/SeniorDesign/bma400_sample/boards/nrf52dk_nrf52832.overlay:23 */
			#pwm-cells = < 0x3 >;          /* in zephyr/dts/arm/nordic/nrf52832.dtsi:399 */
			pinctrl-0 = < &pwm0_default >; /* in zephyr/boards/nordic/nrf52dk/nrf52dk_nrf52832.dts:198 */
			pinctrl-1 = < &pwm0_sleep >;   /* in zephyr/boards/nordic/nrf52dk/nrf52dk_nrf52832.dts:199 */
			pinctrl-names = "default",
			                "sleep";       /* in zephyr/boards/nordic/nrf52dk/nrf52dk_nrf52832.dts:200 */
			phandle = < 0x14 >;            /* in zephyr/boards/nordic/nrf52dk/nrf52dk_nrf52832.dts:56 */
		};

		/* node '/soc/pdm@4001d000' defined in zephyr/dts/arm/nordic/nrf52832.dtsi:402 */
		pdm0: pdm@4001d000 {
			compatible = "nordic,nrf-pdm"; /* in zephyr/dts/arm/nordic/nrf52832.dtsi:403 */
			reg = < 0x4001d000 0x1000 >;   /* in zephyr/dts/arm/nordic/nrf52832.dtsi:404 */
			interrupts = < 0x1d 0x1 >;     /* in zephyr/dts/arm/nordic/nrf52832.dtsi:405 */
			status = "disabled";           /* in zephyr/dts/arm/nordic/nrf52832.dtsi:406 */
		};

		/* node '/soc/flash-controller@4001e000' defined in zephyr/dts/arm/nordic/nrf52832.dtsi:409 */
		flash_controller: flash-controller@4001e000 {
			compatible = "nordic,nrf52-flash-controller"; /* in zephyr/dts/arm/nordic/nrf52832.dtsi:410 */
			reg = < 0x4001e000 0x1000 >;                  /* in zephyr/dts/arm/nordic/nrf52832.dtsi:411 */
			#address-cells = < 0x1 >;                     /* in zephyr/dts/arm/nordic/nrf52832.dtsi:413 */
			#size-cells = < 0x1 >;                        /* in zephyr/dts/arm/nordic/nrf52832.dtsi:414 */

			/* node '/soc/flash-controller@4001e000/flash@0' defined in zephyr/dts/arm/nordic/nrf52832.dtsi:417 */
			flash0: flash@0 {
				compatible = "soc-nv-flash";   /* in zephyr/dts/arm/nordic/nrf52832.dtsi:418 */
				erase-block-size = < 0x1000 >; /* in zephyr/dts/arm/nordic/nrf52832.dtsi:419 */
				write-block-size = < 0x4 >;    /* in zephyr/dts/arm/nordic/nrf52832.dtsi:420 */
				reg = < 0x0 0x80000 >;         /* in zephyr/dts/arm/nordic/nrf52832_qfaa.dtsi:11 */

				/* node '/soc/flash-controller@4001e000/flash@0/partitions' defined in zephyr/boards/nordic/nrf52dk/nrf52dk_nrf52832.dts:230 */
				partitions {
					compatible = "fixed-partitions"; /* in zephyr/boards/nordic/nrf52dk/nrf52dk_nrf52832.dts:231 */
					#address-cells = < 0x1 >;        /* in zephyr/boards/nordic/nrf52dk/nrf52dk_nrf52832.dts:232 */
					#size-cells = < 0x1 >;           /* in zephyr/boards/nordic/nrf52dk/nrf52dk_nrf52832.dts:233 */

					/* node '/soc/flash-controller@4001e000/flash@0/partitions/partition@0' defined in zephyr/boards/nordic/nrf52dk/nrf52dk_nrf52832.dts:235 */
					boot_partition: partition@0 {
						label = "mcuboot";    /* in zephyr/boards/nordic/nrf52dk/nrf52dk_nrf52832.dts:236 */
						reg = < 0x0 0xc000 >; /* in zephyr/boards/nordic/nrf52dk/nrf52dk_nrf52832.dts:237 */
					};

					/* node '/soc/flash-controller@4001e000/flash@0/partitions/partition@c000' defined in zephyr/boards/nordic/nrf52dk/nrf52dk_nrf52832.dts:240 */
					slot0_partition: partition@c000 {
						label = "image-0";        /* in zephyr/boards/nordic/nrf52dk/nrf52dk_nrf52832.dts:241 */
						reg = < 0xc000 0x37000 >; /* in zephyr/boards/nordic/nrf52dk/nrf52dk_nrf52832.dts:242 */
					};

					/* node '/soc/flash-controller@4001e000/flash@0/partitions/partition@43000' defined in zephyr/boards/nordic/nrf52dk/nrf52dk_nrf52832.dts:245 */
					slot1_partition: partition@43000 {
						label = "image-1";         /* in zephyr/boards/nordic/nrf52dk/nrf52dk_nrf52832.dts:246 */
						reg = < 0x43000 0x37000 >; /* in zephyr/boards/nordic/nrf52dk/nrf52dk_nrf52832.dts:247 */
					};

					/* node '/soc/flash-controller@4001e000/flash@0/partitions/partition@7a000' defined in zephyr/boards/nordic/nrf52dk/nrf52dk_nrf52832.dts:250 */
					storage_partition: partition@7a000 {
						label = "storage";        /* in zephyr/boards/nordic/nrf52dk/nrf52dk_nrf52832.dts:251 */
						reg = < 0x7a000 0x6000 >; /* in zephyr/boards/nordic/nrf52dk/nrf52dk_nrf52832.dts:252 */
					};
				};
			};
		};

		/* node '/soc/ppi@4001f000' defined in zephyr/dts/arm/nordic/nrf52832.dtsi:424 */
		ppi: ppi@4001f000 {
			compatible = "nordic,nrf-ppi"; /* in zephyr/dts/arm/nordic/nrf52832.dtsi:425 */
			reg = < 0x4001f000 0x1000 >;   /* in zephyr/dts/arm/nordic/nrf52832.dtsi:426 */
			status = "okay";               /* in zephyr/dts/arm/nordic/nrf52832.dtsi:427 */
		};

		/* node '/soc/mwu@40020000' defined in zephyr/dts/arm/nordic/nrf52832.dtsi:430 */
		mwu: mwu@40020000 {
			compatible = "nordic,nrf-mwu"; /* in zephyr/dts/arm/nordic/nrf52832.dtsi:431 */
			reg = < 0x40020000 0x1000 >;   /* in zephyr/dts/arm/nordic/nrf52832.dtsi:432 */
			status = "okay";               /* in zephyr/dts/arm/nordic/nrf52832.dtsi:433 */
		};

		/* node '/soc/pwm@40021000' defined in zephyr/dts/arm/nordic/nrf52832.dtsi:436 */
		pwm1: pwm@40021000 {
			compatible = "nordic,nrf-pwm"; /* in zephyr/dts/arm/nordic/nrf52832.dtsi:437 */
			reg = < 0x40021000 0x1000 >;   /* in zephyr/dts/arm/nordic/nrf52832.dtsi:438 */
			interrupts = < 0x21 0x1 >;     /* in zephyr/dts/arm/nordic/nrf52832.dtsi:439 */
			status = "disabled";           /* in zephyr/dts/arm/nordic/nrf52832.dtsi:440 */
			#pwm-cells = < 0x3 >;          /* in zephyr/dts/arm/nordic/nrf52832.dtsi:441 */
		};

		/* node '/soc/pwm@40022000' defined in zephyr/dts/arm/nordic/nrf52832.dtsi:444 */
		pwm2: pwm@40022000 {
			compatible = "nordic,nrf-pwm"; /* in zephyr/dts/arm/nordic/nrf52832.dtsi:445 */
			reg = < 0x40022000 0x1000 >;   /* in zephyr/dts/arm/nordic/nrf52832.dtsi:446 */
			interrupts = < 0x22 0x1 >;     /* in zephyr/dts/arm/nordic/nrf52832.dtsi:447 */
			status = "disabled";           /* in zephyr/dts/arm/nordic/nrf52832.dtsi:448 */
			#pwm-cells = < 0x3 >;          /* in zephyr/dts/arm/nordic/nrf52832.dtsi:449 */
		};

		/* node '/soc/spi@40023000' defined in zephyr/dts/arm/nordic/nrf52832.dtsi:452 */
		spi2: arduino_spi: spi@40023000 {
			compatible = "nordic,nrf-spi";           /* in zephyr/boards/nordic/nrf52dk/nrf52dk_nrf52832.dts:221 */
			#address-cells = < 0x1 >;                /* in zephyr/dts/arm/nordic/nrf52832.dtsi:461 */
			#size-cells = < 0x0 >;                   /* in zephyr/dts/arm/nordic/nrf52832.dtsi:462 */
			reg = < 0x40023000 0x1000 >;             /* in zephyr/dts/arm/nordic/nrf52832.dtsi:463 */
			interrupts = < 0x23 0x1 >;               /* in zephyr/dts/arm/nordic/nrf52832.dtsi:464 */
			max-frequency = < 0x7a1200 >;            /* in zephyr/dts/arm/nordic/nrf52832.dtsi:465 */
			easydma-maxcnt-bits = < 0x8 >;           /* in zephyr/dts/arm/nordic/nrf52832.dtsi:466 */
			status = "disabled";                     /* in ../../Desktop/SeniorDesign/bma400_sample/boards/nrf52dk_nrf52832.overlay:22 */
			cs-gpios = < &arduino_header 0x10 0x1 >; /* in zephyr/boards/nordic/nrf52dk/nrf52dk_nrf52832.dts:223 */
			pinctrl-0 = < &spi2_default >;           /* in zephyr/boards/nordic/nrf52dk/nrf52dk_nrf52832.dts:224 */
			pinctrl-1 = < &spi2_sleep >;             /* in zephyr/boards/nordic/nrf52dk/nrf52dk_nrf52832.dts:225 */
			pinctrl-names = "default",
			                "sleep";                 /* in zephyr/boards/nordic/nrf52dk/nrf52dk_nrf52832.dts:226 */
		};

		/* node '/soc/rtc@40024000' defined in zephyr/dts/arm/nordic/nrf52832.dtsi:470 */
		rtc2: rtc@40024000 {
			compatible = "nordic,nrf-rtc"; /* in zephyr/dts/arm/nordic/nrf52832.dtsi:471 */
			reg = < 0x40024000 0x1000 >;   /* in zephyr/dts/arm/nordic/nrf52832.dtsi:472 */
			cc-num = < 0x4 >;              /* in zephyr/dts/arm/nordic/nrf52832.dtsi:473 */
			interrupts = < 0x24 0x1 >;     /* in zephyr/dts/arm/nordic/nrf52832.dtsi:474 */
			status = "disabled";           /* in zephyr/dts/arm/nordic/nrf52832.dtsi:475 */
			clock-frequency = < 0x8000 >;  /* in zephyr/dts/arm/nordic/nrf52832.dtsi:476 */
			prescaler = < 0x1 >;           /* in zephyr/dts/arm/nordic/nrf52832.dtsi:477 */
		};

		/* node '/soc/i2s@40025000' defined in zephyr/dts/arm/nordic/nrf52832.dtsi:480 */
		i2s0: i2s@40025000 {
			compatible = "nordic,nrf-i2s"; /* in zephyr/dts/arm/nordic/nrf52832.dtsi:481 */
			#address-cells = < 0x1 >;      /* in zephyr/dts/arm/nordic/nrf52832.dtsi:482 */
			#size-cells = < 0x0 >;         /* in zephyr/dts/arm/nordic/nrf52832.dtsi:483 */
			reg = < 0x40025000 0x1000 >;   /* in zephyr/dts/arm/nordic/nrf52832.dtsi:484 */
			interrupts = < 0x25 0x1 >;     /* in zephyr/dts/arm/nordic/nrf52832.dtsi:485 */
			status = "disabled";           /* in zephyr/dts/arm/nordic/nrf52832.dtsi:486 */
		};

		/* node '/soc/gpio@50000000' defined in zephyr/dts/arm/nordic/nrf52832.dtsi:489 */
		gpio0: gpio@50000000 {
			compatible = "nordic,nrf-gpio";   /* in zephyr/dts/arm/nordic/nrf52832.dtsi:490 */
			gpio-controller;                  /* in zephyr/dts/arm/nordic/nrf52832.dtsi:491 */
			reg = < 0x50000000 0x1000 >;      /* in zephyr/dts/arm/nordic/nrf52832.dtsi:492 */
			#gpio-cells = < 0x2 >;            /* in zephyr/dts/arm/nordic/nrf52832.dtsi:493 */
			status = "okay";                  /* in ../../Desktop/SeniorDesign/bma400_sample/boards/nrf52dk_nrf52832.overlay:26 */
			port = < 0x0 >;                   /* in zephyr/dts/arm/nordic/nrf52832.dtsi:495 */
			gpiote-instance = < &gpiote >;    /* in zephyr/dts/arm/nordic/nrf52832.dtsi:496 */
			sense-edge-mask = < 0xffffffff >; /* in ../../Desktop/SeniorDesign/bma400_sample/boards/nrf52dk_nrf52832.overlay:27 */
			phandle = < 0xc >;                /* in ../../Desktop/SeniorDesign/bma400_sample/boards/nrf52dk_nrf52832.overlay:36 */
		};
	};

	/* node '/pin-controller' defined in zephyr/dts/vendor/nordic/nrf_common.dtsi:25 */
	pinctrl: pin-controller {
		compatible = "nordic,nrf-pinctrl"; /* in zephyr/dts/vendor/nordic/nrf_common.dtsi:30 */

		/* node '/pin-controller/uart0_default' defined in zephyr/boards/nordic/nrf52dk/nrf52dk_nrf52832-pinctrl.dtsi:7 */
		uart0_default: uart0_default {
			phandle = < 0x2 >; /* in zephyr/boards/nordic/nrf52dk/nrf52dk_nrf52832.dts:174 */

			/* node '/pin-controller/uart0_default/group1' defined in zephyr/boards/nordic/nrf52dk/nrf52dk_nrf52832-pinctrl.dtsi:8 */
			group1 {
				psels = < 0x6 >,
				        < 0x1000008 >,
				        < 0x2000005 >,
				        < 0x3000007 >; /* in zephyr/boards/nordic/nrf52dk/nrf52dk_nrf52832-pinctrl.dtsi:9 */
			};
		};

		/* node '/pin-controller/uart0_sleep' defined in zephyr/boards/nordic/nrf52dk/nrf52dk_nrf52832-pinctrl.dtsi:16 */
		uart0_sleep: uart0_sleep {
			phandle = < 0x3 >; /* in zephyr/boards/nordic/nrf52dk/nrf52dk_nrf52832.dts:175 */

			/* node '/pin-controller/uart0_sleep/group1' defined in zephyr/boards/nordic/nrf52dk/nrf52dk_nrf52832-pinctrl.dtsi:17 */
			group1 {
				psels = < 0x6 >,
				        < 0x1000008 >,
				        < 0x2000005 >,
				        < 0x3000007 >; /* in zephyr/boards/nordic/nrf52dk/nrf52dk_nrf52832-pinctrl.dtsi:18 */
				low-power-enable;      /* in zephyr/boards/nordic/nrf52dk/nrf52dk_nrf52832-pinctrl.dtsi:22 */
			};
		};

		/* node '/pin-controller/i2c0_default' defined in zephyr/boards/nordic/nrf52dk/nrf52dk_nrf52832-pinctrl.dtsi:26 */
		i2c0_default: i2c0_default {
			phandle = < 0x4 >; /* in zephyr/boards/nordic/nrf52dk/nrf52dk_nrf52832.dts:182 */

			/* node '/pin-controller/i2c0_default/group1' defined in zephyr/boards/nordic/nrf52dk/nrf52dk_nrf52832-pinctrl.dtsi:27 */
			group1 {
				psels = < 0xc00001a >,
				        < 0xb00001b >; /* in zephyr/boards/nordic/nrf52dk/nrf52dk_nrf52832-pinctrl.dtsi:28 */
			};
		};

		/* node '/pin-controller/i2c0_sleep' defined in zephyr/boards/nordic/nrf52dk/nrf52dk_nrf52832-pinctrl.dtsi:33 */
		i2c0_sleep: i2c0_sleep {
			phandle = < 0x5 >; /* in zephyr/boards/nordic/nrf52dk/nrf52dk_nrf52832.dts:183 */

			/* node '/pin-controller/i2c0_sleep/group1' defined in zephyr/boards/nordic/nrf52dk/nrf52dk_nrf52832-pinctrl.dtsi:34 */
			group1 {
				psels = < 0xc00001a >,
				        < 0xb00001b >; /* in zephyr/boards/nordic/nrf52dk/nrf52dk_nrf52832-pinctrl.dtsi:35 */
				low-power-enable;      /* in zephyr/boards/nordic/nrf52dk/nrf52dk_nrf52832-pinctrl.dtsi:37 */
			};
		};

		/* node '/pin-controller/i2c1_default' defined in zephyr/boards/nordic/nrf52dk/nrf52dk_nrf52832-pinctrl.dtsi:41 */
		i2c1_default: i2c1_default {
			phandle = < 0x8 >; /* in zephyr/boards/nordic/nrf52dk/nrf52dk_nrf52832.dts:191 */

			/* node '/pin-controller/i2c1_default/group1' defined in zephyr/boards/nordic/nrf52dk/nrf52dk_nrf52832-pinctrl.dtsi:42 */
			group1 {
				psels = < 0xc00001e >,
				        < 0xb00001f >; /* in zephyr/boards/nordic/nrf52dk/nrf52dk_nrf52832-pinctrl.dtsi:43 */
			};
		};

		/* node '/pin-controller/i2c1_sleep' defined in zephyr/boards/nordic/nrf52dk/nrf52dk_nrf52832-pinctrl.dtsi:48 */
		i2c1_sleep: i2c1_sleep {
			phandle = < 0x9 >; /* in zephyr/boards/nordic/nrf52dk/nrf52dk_nrf52832.dts:192 */

			/* node '/pin-controller/i2c1_sleep/group1' defined in zephyr/boards/nordic/nrf52dk/nrf52dk_nrf52832-pinctrl.dtsi:49 */
			group1 {
				psels = < 0xc00001e >,
				        < 0xb00001f >; /* in zephyr/boards/nordic/nrf52dk/nrf52dk_nrf52832-pinctrl.dtsi:50 */
				low-power-enable;      /* in zephyr/boards/nordic/nrf52dk/nrf52dk_nrf52832-pinctrl.dtsi:52 */
			};
		};

		/* node '/pin-controller/pwm0_default' defined in zephyr/boards/nordic/nrf52dk/nrf52dk_nrf52832-pinctrl.dtsi:56 */
		pwm0_default: pwm0_default {
			phandle = < 0xd >; /* in zephyr/boards/nordic/nrf52dk/nrf52dk_nrf52832.dts:198 */

			/* node '/pin-controller/pwm0_default/group1' defined in zephyr/boards/nordic/nrf52dk/nrf52dk_nrf52832-pinctrl.dtsi:57 */
			group1 {
				psels = < 0x16000011 >; /* in zephyr/boards/nordic/nrf52dk/nrf52dk_nrf52832-pinctrl.dtsi:58 */
				nordic,invert;          /* in zephyr/boards/nordic/nrf52dk/nrf52dk_nrf52832-pinctrl.dtsi:59 */
			};
		};

		/* node '/pin-controller/pwm0_sleep' defined in zephyr/boards/nordic/nrf52dk/nrf52dk_nrf52832-pinctrl.dtsi:63 */
		pwm0_sleep: pwm0_sleep {
			phandle = < 0xe >; /* in zephyr/boards/nordic/nrf52dk/nrf52dk_nrf52832.dts:199 */

			/* node '/pin-controller/pwm0_sleep/group1' defined in zephyr/boards/nordic/nrf52dk/nrf52dk_nrf52832-pinctrl.dtsi:64 */
			group1 {
				psels = < 0x16000011 >; /* in zephyr/boards/nordic/nrf52dk/nrf52dk_nrf52832-pinctrl.dtsi:65 */
				low-power-enable;       /* in zephyr/boards/nordic/nrf52dk/nrf52dk_nrf52832-pinctrl.dtsi:66 */
			};
		};

		/* node '/pin-controller/spi0_default' defined in zephyr/boards/nordic/nrf52dk/nrf52dk_nrf52832-pinctrl.dtsi:70 */
		spi0_default: spi0_default {
			phandle = < 0x6 >; /* in zephyr/boards/nordic/nrf52dk/nrf52dk_nrf52832.dts:207 */

			/* node '/pin-controller/spi0_default/group1' defined in zephyr/boards/nordic/nrf52dk/nrf52dk_nrf52832-pinctrl.dtsi:71 */
			group1 {
				psels = < 0x400001b >,
				        < 0x500001a >,
				        < 0x600001c >; /* in zephyr/boards/nordic/nrf52dk/nrf52dk_nrf52832-pinctrl.dtsi:72 */
			};
		};

		/* node '/pin-controller/spi0_sleep' defined in zephyr/boards/nordic/nrf52dk/nrf52dk_nrf52832-pinctrl.dtsi:78 */
		spi0_sleep: spi0_sleep {
			phandle = < 0x7 >; /* in zephyr/boards/nordic/nrf52dk/nrf52dk_nrf52832.dts:208 */

			/* node '/pin-controller/spi0_sleep/group1' defined in zephyr/boards/nordic/nrf52dk/nrf52dk_nrf52832-pinctrl.dtsi:79 */
			group1 {
				psels = < 0x400001b >,
				        < 0x500001a >,
				        < 0x600001c >; /* in zephyr/boards/nordic/nrf52dk/nrf52dk_nrf52832-pinctrl.dtsi:80 */
				low-power-enable;      /* in zephyr/boards/nordic/nrf52dk/nrf52dk_nrf52832-pinctrl.dtsi:83 */
			};
		};

		/* node '/pin-controller/spi1_default' defined in zephyr/boards/nordic/nrf52dk/nrf52dk_nrf52832-pinctrl.dtsi:87 */
		spi1_default: spi1_default {
			phandle = < 0xa >; /* in ../../Desktop/SeniorDesign/bma400_sample/boards/nrf52dk_nrf52832.overlay:33 */

			/* node '/pin-controller/spi1_default/group1' defined in zephyr/boards/nordic/nrf52dk/nrf52dk_nrf52832-pinctrl.dtsi:88 */
			group1 {
				psels = < 0x400001c >,
				        < 0x500001d >,
				        < 0x600001e >; /* in ../../Desktop/SeniorDesign/bma400_sample/boards/nrf52dk_nrf52832.overlay:47 */
			};
		};

		/* node '/pin-controller/spi1_sleep' defined in zephyr/boards/nordic/nrf52dk/nrf52dk_nrf52832-pinctrl.dtsi:95 */
		spi1_sleep: spi1_sleep {
			phandle = < 0xb >; /* in ../../Desktop/SeniorDesign/bma400_sample/boards/nrf52dk_nrf52832.overlay:34 */

			/* node '/pin-controller/spi1_sleep/group1' defined in zephyr/boards/nordic/nrf52dk/nrf52dk_nrf52832-pinctrl.dtsi:96 */
			group1 {
				psels = < 0x400001c >,
				        < 0x500001d >,
				        < 0x600001e >; /* in ../../Desktop/SeniorDesign/bma400_sample/boards/nrf52dk_nrf52832.overlay:54 */
				low-power-enable;      /* in ../../Desktop/SeniorDesign/bma400_sample/boards/nrf52dk_nrf52832.overlay:57 */
			};
		};

		/* node '/pin-controller/spi2_default' defined in zephyr/boards/nordic/nrf52dk/nrf52dk_nrf52832-pinctrl.dtsi:104 */
		spi2_default: spi2_default {
			phandle = < 0x10 >; /* in zephyr/boards/nordic/nrf52dk/nrf52dk_nrf52832.dts:224 */

			/* node '/pin-controller/spi2_default/group1' defined in zephyr/boards/nordic/nrf52dk/nrf52dk_nrf52832-pinctrl.dtsi:105 */
			group1 {
				psels = < 0x4000019 >,
				        < 0x5000017 >,
				        < 0x6000018 >; /* in zephyr/boards/nordic/nrf52dk/nrf52dk_nrf52832-pinctrl.dtsi:106 */
			};
		};

		/* node '/pin-controller/spi2_sleep' defined in zephyr/boards/nordic/nrf52dk/nrf52dk_nrf52832-pinctrl.dtsi:112 */
		spi2_sleep: spi2_sleep {
			phandle = < 0x11 >; /* in zephyr/boards/nordic/nrf52dk/nrf52dk_nrf52832.dts:225 */

			/* node '/pin-controller/spi2_sleep/group1' defined in zephyr/boards/nordic/nrf52dk/nrf52dk_nrf52832-pinctrl.dtsi:113 */
			group1 {
				psels = < 0x4000019 >,
				        < 0x5000017 >,
				        < 0x6000018 >; /* in zephyr/boards/nordic/nrf52dk/nrf52dk_nrf52832-pinctrl.dtsi:114 */
				low-power-enable;      /* in zephyr/boards/nordic/nrf52dk/nrf52dk_nrf52832-pinctrl.dtsi:117 */
			};
		};
	};

	/* node '/entropy_bt_hci' defined in zephyr/dts/vendor/nordic/nrf_common.dtsi:33 */
	rng_hci: entropy_bt_hci {
		compatible = "zephyr,bt-hci-entropy"; /* in zephyr/dts/vendor/nordic/nrf_common.dtsi:34 */
		status = "okay";                      /* in zephyr/dts/vendor/nordic/nrf_common.dtsi:35 */
	};

	/* node '/sw-pwm' defined in zephyr/dts/vendor/nordic/nrf_common.dtsi:38 */
	sw_pwm: sw-pwm {
		compatible = "nordic,nrf-sw-pwm"; /* in zephyr/dts/vendor/nordic/nrf_common.dtsi:39 */
		status = "disabled";              /* in zephyr/dts/vendor/nordic/nrf_common.dtsi:40 */
		generator = < &timer1 >;          /* in zephyr/dts/vendor/nordic/nrf_common.dtsi:41 */
		clock-prescaler = < 0x0 >;        /* in zephyr/dts/vendor/nordic/nrf_common.dtsi:42 */
		#pwm-cells = < 0x3 >;             /* in zephyr/dts/vendor/nordic/nrf_common.dtsi:43 */
	};

	/* node '/cpus' defined in zephyr/dts/arm/nordic/nrf52832.dtsi:15 */
	cpus {
		#address-cells = < 0x1 >; /* in zephyr/dts/arm/nordic/nrf52832.dtsi:16 */
		#size-cells = < 0x0 >;    /* in zephyr/dts/arm/nordic/nrf52832.dtsi:17 */

		/* node '/cpus/cpu@0' defined in zephyr/dts/arm/nordic/nrf52832.dtsi:19 */
		cpu@0 {
			device_type = "cpu";           /* in zephyr/dts/arm/nordic/nrf52832.dtsi:20 */
			compatible = "arm,cortex-m4f"; /* in zephyr/dts/arm/nordic/nrf52832.dtsi:21 */
			reg = < 0x0 >;                 /* in zephyr/dts/arm/nordic/nrf52832.dtsi:22 */
			#address-cells = < 0x1 >;      /* in zephyr/dts/arm/nordic/nrf52832.dtsi:23 */
			#size-cells = < 0x1 >;         /* in zephyr/dts/arm/nordic/nrf52832.dtsi:24 */

			/* node '/cpus/cpu@0/itm@e0000000' defined in zephyr/dts/arm/nordic/nrf52832.dtsi:26 */
			itm: itm@e0000000 {
				compatible = "arm,armv7m-itm";     /* in zephyr/dts/arm/nordic/nrf52832.dtsi:27 */
				reg = < 0xe0000000 0x1000 >;       /* in zephyr/dts/arm/nordic/nrf52832.dtsi:28 */
				swo-ref-frequency = < 0x1e84800 >; /* in zephyr/dts/arm/nordic/nrf52832.dtsi:29 */
			};
		};
	};

	/* node '/clocks' defined in zephyr/dts/arm/nordic/nrf52832.dtsi:34 */
	clocks {

		/* node '/clocks/hfxo' defined in zephyr/dts/arm/nordic/nrf52832.dtsi:35 */
		hfxo: hfxo {
			compatible = "nordic,nrf52-hfxo"; /* in zephyr/dts/arm/nordic/nrf52832.dtsi:36 */
			clock-frequency = < 0x3d09000 >;  /* in zephyr/dts/arm/nordic/nrf52832.dtsi:37 */
			startup-time-us = < 0x578 >;      /* in zephyr/dts/arm/nordic/nrf52832.dtsi:38 */
			#clock-cells = < 0x0 >;           /* in zephyr/dts/arm/nordic/nrf52832.dtsi:39 */
		};
	};

	/* node '/leds' defined in zephyr/boards/nordic/nrf52dk/nrf52dk_nrf52832.dts:28 */
	leds {
		compatible = "gpio-leds"; /* in zephyr/boards/nordic/nrf52dk/nrf52dk_nrf52832.dts:29 */

		/* node '/leds/led_0' defined in zephyr/boards/nordic/nrf52dk/nrf52dk_nrf52832.dts:31 */
		led0: led_0 {
			gpios = < &gpio0 0x11 0x1 >; /* in zephyr/boards/nordic/nrf52dk/nrf52dk_nrf52832.dts:32 */
			label = "Green LED 0";       /* in zephyr/boards/nordic/nrf52dk/nrf52dk_nrf52832.dts:33 */
		};

		/* node '/leds/led_1' defined in zephyr/boards/nordic/nrf52dk/nrf52dk_nrf52832.dts:36 */
		led1: led_1 {
			gpios = < &gpio0 0x12 0x1 >; /* in zephyr/boards/nordic/nrf52dk/nrf52dk_nrf52832.dts:37 */
			label = "Green LED 1";       /* in zephyr/boards/nordic/nrf52dk/nrf52dk_nrf52832.dts:38 */
		};

		/* node '/leds/led_2' defined in zephyr/boards/nordic/nrf52dk/nrf52dk_nrf52832.dts:41 */
		led2: led_2 {
			gpios = < &gpio0 0x13 0x1 >; /* in zephyr/boards/nordic/nrf52dk/nrf52dk_nrf52832.dts:42 */
			label = "Green LED 2";       /* in zephyr/boards/nordic/nrf52dk/nrf52dk_nrf52832.dts:43 */
		};

		/* node '/leds/led_3' defined in zephyr/boards/nordic/nrf52dk/nrf52dk_nrf52832.dts:46 */
		led3: led_3 {
			gpios = < &gpio0 0x14 0x1 >; /* in zephyr/boards/nordic/nrf52dk/nrf52dk_nrf52832.dts:47 */
			label = "Green LED 3";       /* in zephyr/boards/nordic/nrf52dk/nrf52dk_nrf52832.dts:48 */
		};
	};

	/* node '/pwmleds' defined in zephyr/boards/nordic/nrf52dk/nrf52dk_nrf52832.dts:52 */
	pwmleds {
		compatible = "pwm-leds"; /* in zephyr/boards/nordic/nrf52dk/nrf52dk_nrf52832.dts:53 */

		/* node '/pwmleds/pwm_led_0' defined in zephyr/boards/nordic/nrf52dk/nrf52dk_nrf52832.dts:55 */
		pwm_led0: pwm_led_0 {
			pwms = < &pwm0 0x0 0x1312d00 0x1 >; /* in zephyr/boards/nordic/nrf52dk/nrf52dk_nrf52832.dts:56 */
		};
	};

	/* node '/buttons' defined in zephyr/boards/nordic/nrf52dk/nrf52dk_nrf52832.dts:60 */
	buttons {
		compatible = "gpio-keys"; /* in zephyr/boards/nordic/nrf52dk/nrf52dk_nrf52832.dts:61 */

		/* node '/buttons/button_0' defined in zephyr/boards/nordic/nrf52dk/nrf52dk_nrf52832.dts:63 */
		button0: button_0 {
			gpios = < &gpio0 0xd 0x11 >;    /* in zephyr/boards/nordic/nrf52dk/nrf52dk_nrf52832.dts:64 */
			label = "Push button switch 0"; /* in zephyr/boards/nordic/nrf52dk/nrf52dk_nrf52832.dts:65 */
			zephyr,code = < 0xb >;          /* in zephyr/boards/nordic/nrf52dk/nrf52dk_nrf52832.dts:66 */
		};

		/* node '/buttons/button_1' defined in zephyr/boards/nordic/nrf52dk/nrf52dk_nrf52832.dts:69 */
		button1: button_1 {
			gpios = < &gpio0 0xe 0x11 >;    /* in zephyr/boards/nordic/nrf52dk/nrf52dk_nrf52832.dts:70 */
			label = "Push button switch 1"; /* in zephyr/boards/nordic/nrf52dk/nrf52dk_nrf52832.dts:71 */
			zephyr,code = < 0x2 >;          /* in zephyr/boards/nordic/nrf52dk/nrf52dk_nrf52832.dts:72 */
		};

		/* node '/buttons/button_2' defined in zephyr/boards/nordic/nrf52dk/nrf52dk_nrf52832.dts:75 */
		button2: button_2 {
			gpios = < &gpio0 0xf 0x11 >;    /* in zephyr/boards/nordic/nrf52dk/nrf52dk_nrf52832.dts:76 */
			label = "Push button switch 2"; /* in zephyr/boards/nordic/nrf52dk/nrf52dk_nrf52832.dts:77 */
			zephyr,code = < 0x3 >;          /* in zephyr/boards/nordic/nrf52dk/nrf52dk_nrf52832.dts:78 */
		};

		/* node '/buttons/button_3' defined in zephyr/boards/nordic/nrf52dk/nrf52dk_nrf52832.dts:81 */
		button3: button_3 {
			gpios = < &gpio0 0x10 0x11 >;   /* in zephyr/boards/nordic/nrf52dk/nrf52dk_nrf52832.dts:82 */
			label = "Push button switch 3"; /* in zephyr/boards/nordic/nrf52dk/nrf52dk_nrf52832.dts:83 */
			zephyr,code = < 0x4 >;          /* in zephyr/boards/nordic/nrf52dk/nrf52dk_nrf52832.dts:84 */
		};
	};

	/* node '/connector' defined in zephyr/boards/nordic/nrf52dk/nrf52dk_nrf52832.dts:88 */
	arduino_header: connector {
		compatible = "arduino-header-r3";          /* in zephyr/boards/nordic/nrf52dk/nrf52dk_nrf52832.dts:89 */
		#gpio-cells = < 0x2 >;                     /* in zephyr/boards/nordic/nrf52dk/nrf52dk_nrf52832.dts:90 */
		gpio-map-mask = < 0xffffffff 0xffffffc0 >; /* in zephyr/boards/nordic/nrf52dk/nrf52dk_nrf52832.dts:91 */
		gpio-map-pass-thru = < 0x0 0x3f >;         /* in zephyr/boards/nordic/nrf52dk/nrf52dk_nrf52832.dts:92 */
		gpio-map = < 0x0 0x0 &gpio0 0x3 0x0 >,
		           < 0x1 0x0 &gpio0 0x4 0x0 >,
		           < 0x2 0x0 &gpio0 0x1c 0x0 >,
		           < 0x3 0x0 &gpio0 0x1d 0x0 >,
		           < 0x4 0x0 &gpio0 0x1e 0x0 >,
		           < 0x5 0x0 &gpio0 0x1f 0x0 >,
		           < 0x6 0x0 &gpio0 0xb 0x0 >,
		           < 0x7 0x0 &gpio0 0xc 0x0 >,
		           < 0x8 0x0 &gpio0 0xd 0x0 >,
		           < 0x9 0x0 &gpio0 0xe 0x0 >,
		           < 0xa 0x0 &gpio0 0xf 0x0 >,
		           < 0xb 0x0 &gpio0 0x10 0x0 >,
		           < 0xc 0x0 &gpio0 0x11 0x0 >,
		           < 0xd 0x0 &gpio0 0x12 0x0 >,
		           < 0xe 0x0 &gpio0 0x13 0x0 >,
		           < 0xf 0x0 &gpio0 0x14 0x0 >,
		           < 0x10 0x0 &gpio0 0x16 0x0 >,
		           < 0x11 0x0 &gpio0 0x17 0x0 >,
		           < 0x12 0x0 &gpio0 0x18 0x0 >,
		           < 0x13 0x0 &gpio0 0x19 0x0 >,
		           < 0x14 0x0 &gpio0 0x1a 0x0 >,
		           < 0x15 0x0 &gpio0 0x1b 0x0 >;   /* in zephyr/boards/nordic/nrf52dk/nrf52dk_nrf52832.dts:93 */
		phandle = < 0xf >;                         /* in zephyr/boards/nordic/nrf52dk/nrf52dk_nrf52832.dts:223 */
	};

	/* node '/analog-connector' defined in zephyr/boards/nordic/nrf52dk/nrf52dk_nrf52832.dts:117 */
	arduino_adc: analog-connector {
		compatible = "arduino,uno-adc";    /* in zephyr/boards/nordic/nrf52dk/nrf52dk_nrf52832.dts:118 */
		#io-channel-cells = < 0x1 >;       /* in zephyr/boards/nordic/nrf52dk/nrf52dk_nrf52832.dts:119 */
		io-channel-map = < 0x0 &adc 0x1 >,
		                 < 0x1 &adc 0x2 >,
		                 < 0x2 &adc 0x4 >,
		                 < 0x3 &adc 0x5 >,
		                 < 0x4 &adc 0x6 >,
		                 < 0x5 &adc 0x7 >; /* in zephyr/boards/nordic/nrf52dk/nrf52dk_nrf52832.dts:120 */
	};

	/* node '/inputs' defined in ../../Desktop/SeniorDesign/bma400_sample/boards/nrf52dk_nrf52832.overlay:4 */
	inputs {
		compatible = "gpio-keys"; /* in ../../Desktop/SeniorDesign/bma400_sample/boards/nrf52dk_nrf52832.overlay:5 */

		/* node '/inputs/bmaint_1' defined in ../../Desktop/SeniorDesign/bma400_sample/boards/nrf52dk_nrf52832.overlay:6 */
		bmaint1: bmaint_1 {
			gpios = < &gpio0 0x1b 0x20 >; /* in ../../Desktop/SeniorDesign/bma400_sample/boards/nrf52dk_nrf52832.overlay:7 */
			label = "BMA400 Interrupt 2"; /* in ../../Desktop/SeniorDesign/bma400_sample/boards/nrf52dk_nrf52832.overlay:8 */
		};
	};
};
